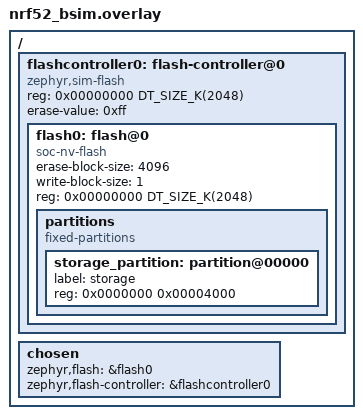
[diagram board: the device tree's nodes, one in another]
/*
 * Copyright (c) 2023 Nordic Semiconductor ASA
 *
 * SPDX-License-Identifier: Apache-2.0
 */

/ {
	flashcontroller0: flash-controller@0 {
		compatible = "zephyr,sim-flash";
		reg = <0x00000000 DT_SIZE_K(2048)>;

		#address-cells = <1>;
		#size-cells = <1>;
		erase-value = <0xff>;

		flash0: flash@0 {
			status = "okay";
			compatible = "soc-nv-flash";
			erase-block-size = <4096>;
			write-block-size = <1>;
			reg = <0x00000000 DT_SIZE_K(2048)>;

			partitions {
				compatible = "fixed-partitions";
				#address-cells = <1>;
				#size-cells = <1>;

				storage_partition: partition@00000 {
					label = "storage";
					reg = <0x0000000 0x00004000>;
				};
			};
		};
	};

	chosen {
		zephyr,flash = &flash0;
		zephyr,flash-controller = &flashcontroller0;
	};
};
